# STM32F205RBT6 register map
File version: 1.0
Registers are 32-bit, access not given, reset 0x0 unless marked. A register's access mark holds for its fields unless they carry their own. Offsets are from the block's base; [hi:lo] are bit positions; {n}, {i} and the like mark numbered series.

## ADC1
Base 0x40012000
Same registers: ADC2 0x40012100, ADC3 0x40012300
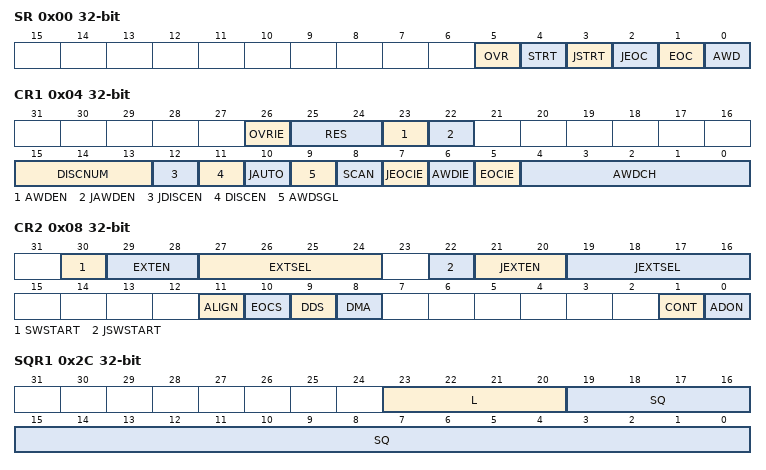
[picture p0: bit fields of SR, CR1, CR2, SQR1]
0x00 SR
  [5] OVR, [4] STRT, [3] JSTRT, [2] JEOC, [1] EOC, [0] AWD
0x04 CR1
  [26] OVRIE, [25:24] RES, [23] AWDEN, [22] JAWDEN, [15:13] DISCNUM, [12] JDISCEN, [11] DISCEN, [10] JAUTO, [9] AWDSGL, [8] SCAN, [7] JEOCIE, [6] AWDIE, [5] EOCIE, [4:0] AWDCH
0x08 CR2
  [30] SWSTART, [29:28] EXTEN, [27:24] EXTSEL, [22] JSWSTART, [21:20] JEXTEN, [19:16] JEXTSEL, [11] ALIGN, [10] EOCS, [9] DDS, [8] DMA, [1] CONT, [0] ADON
0x0C SMPR1
  [31:0] SMP
0x10 SMPR2
  [31:0] SMP
{0x10+4i} JOFR{i} (i=1..4)
  [11:0] JOFFSET{i}
0x24 HTR
  [11:0] HT
0x28 LTR
  [11:0] LT
0x2C SQR1
  [23:20] L, [19:0] SQ
0x30 SQR2
  [29:0] SQ
0x34 SQR3
  [29:0] SQ
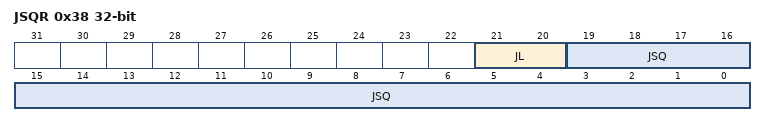
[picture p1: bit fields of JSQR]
0x38 JSQR
  [21:20] JL, [19:0] JSQ
{0x38+4i} JDR{i} (i=1..4)
  [15:0] JDATA
0x4C DR
  [15:0] DATA

## SDIO
Base 0x40012C00
0x00 POWER
  [1:0] PWRCTRL
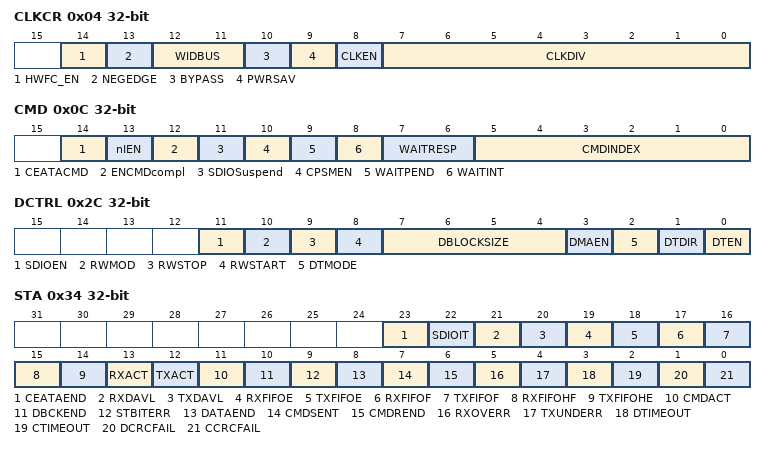
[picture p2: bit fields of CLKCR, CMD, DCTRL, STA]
0x04 CLKCR
  [14] HWFC_EN, [13] NEGEDGE, [12:11] WIDBUS, [10] BYPASS, [9] PWRSAV, [8] CLKEN, [7:0] CLKDIV
0x08 ARG
  [31:0] CMDARG
0x0C CMD
  [14] CEATACMD, [13] nIEN, [12] ENCMDcompl, [11] SDIOSuspend, [10] CPSMEN, [9] WAITPEND, [8] WAITINT, [7:6] WAITRESP, [5:0] CMDINDEX
0x10 RESPCMD
  [5:0] RESPCMD
{0x10+4i} RESP{i} (i=1..4)
  [31:0] CARDSTATUS{i}
0x24 DTIMER
  [31:0] DATATIME
0x28 DLEN
  [24:0] DATALENGTH
0x2C DCTRL
  [11] SDIOEN, [10] RWMOD, [9] RWSTOP, [8] RWSTART, [7:4] DBLOCKSIZE, [3] DMAEN, [2] DTMODE, [1] DTDIR, [0] DTEN
0x30 DCOUNT
  [24:0] DATACOUNT
0x34 STA
  [23] CEATAEND, [22] SDIOIT, [21] RXDAVL, [20] TXDAVL, [19] RXFIFOE, [18] TXFIFOE, [17] RXFIFOF, [16] TXFIFOF, [15] RXFIFOHF, [14] TXFIFOHE, [13] RXACT, [12] TXACT, [11] CMDACT, [10] DBCKEND, [9] STBITERR, [8] DATAEND, [7] CMDSENT, [6] CMDREND, [5] RXOVERR, [4] TXUNDERR, [3] DTIMEOUT, [2] CTIMEOUT, [1] DCRCFAIL, [0] CCRCFAIL
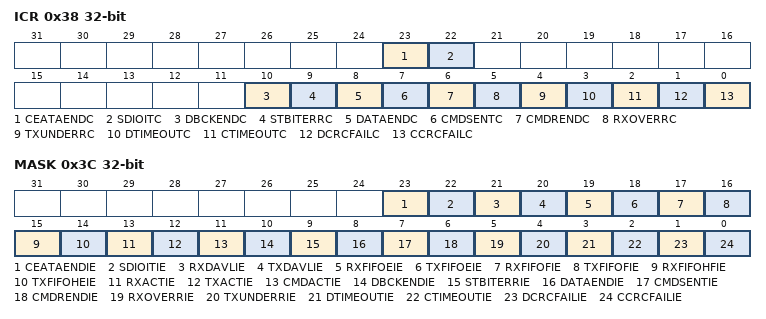
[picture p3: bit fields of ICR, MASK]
0x38 ICR
  [23] CEATAENDC, [22] SDIOITC, [10] DBCKENDC, [9] STBITERRC, [8] DATAENDC, [7] CMDSENTC, [6] CMDRENDC, [5] RXOVERRC, [4] TXUNDERRC, [3] DTIMEOUTC, [2] CTIMEOUTC, [1] DCRCFAILC, [0] CCRCFAILC
0x3C MASK
  [23] CEATAENDIE, [22] SDIOITIE, [21] RXDAVLIE, [20] TXDAVLIE, [19] RXFIFOEIE, [18] TXFIFOEIE, [17] RXFIFOFIE, [16] TXFIFOFIE, [15] RXFIFOHFIE, [14] TXFIFOHEIE, [13] RXACTIE, [12] TXACTIE, [11] CMDACTIE, [10] DBCKENDIE, [9] STBITERRIE, [8] DATAENDIE, [7] CMDSENTIE, [6] CMDRENDIE, [5] RXOVERRIE, [4] TXUNDERRIE, [3] DTIMEOUTIE, [2] CTIMEOUTIE, [1] DCRCFAILIE, [0] CCRCFAILIE
0x48 FIFOCNT
  [23:0] FIFOCOUNT
0x80 FIFO
  [31:0] FIF0Data

## SYSCFG
Base 0x40013800
0x00 MEMRM
  [1:0] MEM_MODE
0x04 PMC
  [23] MII_RMII_SEL
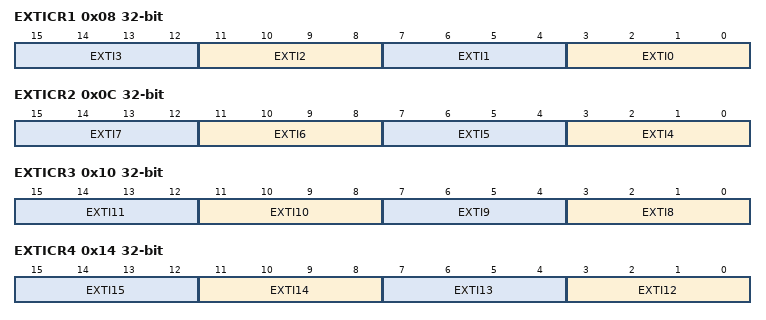
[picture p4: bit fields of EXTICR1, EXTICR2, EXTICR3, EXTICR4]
0x08 EXTICR1
  [4n+3:4n] EXTI{n} (n=0..3)
0x0C EXTICR2
  [4n-13:4n-16] EXTI{n} (n=4..7)
0x10 EXTICR3
  [4n-29:4n-32] EXTI{n} (n=8..11)
0x14 EXTICR4
  [4n-45:4n-48] EXTI{n} (n=12..15)
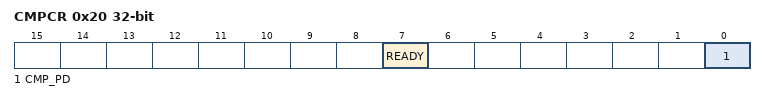
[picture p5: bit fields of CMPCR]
0x20 CMPCR
  [7] READY, [0] CMP_PD

## EXTI
Base 0x40013C00
0x00 IMR
  [22:0] MR
0x04 EMR
  [22:0] MR
0x08 RTSR
  [22:0] TR
0x0C FTSR
  [22:0] TR
0x10 SWIER
  [22:0] SWIER
0x14 PR
  [22:0] PR

## GPIOA
Base 0x40020000
Same registers: GPIOB 0x40020400, GPIOC 0x40020800, GPIOD 0x40020C00, GPIOE 0x40021000, GPIOF 0x40021400, GPIOG 0x40021800, GPIOH 0x40021C00, GPIOI 0x40022000
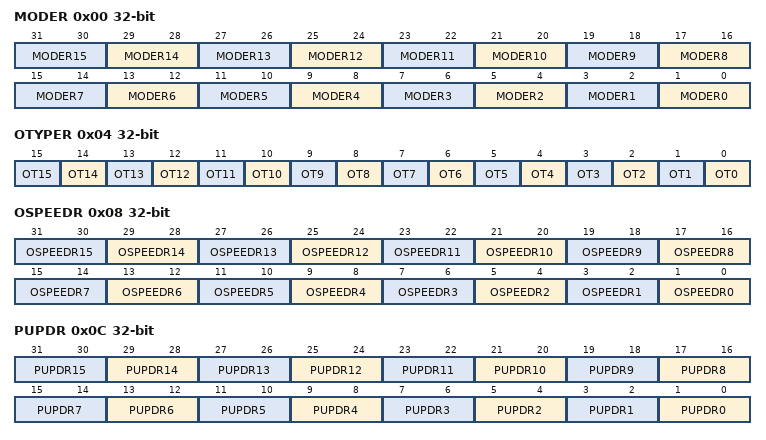
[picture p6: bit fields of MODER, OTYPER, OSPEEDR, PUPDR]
0x00 MODER
  [2n+1:2n] MODER{n} (n=0..15)
0x04 OTYPER
  [n] OT{n} (n=0..15)
0x08 OSPEEDR
  [2n+1:2n] OSPEEDR{n} (n=0..15)
0x0C PUPDR
  [2n+1:2n] PUPDR{n} (n=0..15)
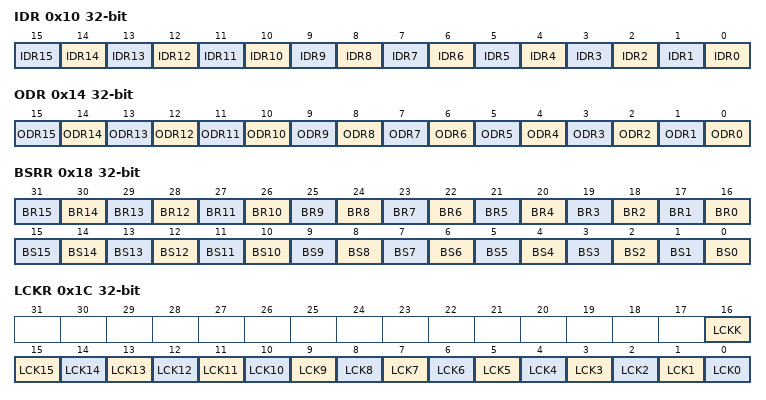
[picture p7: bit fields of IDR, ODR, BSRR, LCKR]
0x10 IDR
  [n] IDR{n} (n=0..15)
0x14 ODR
  [n] ODR{n} (n=0..15)
0x18 BSRR
  [n+16] BR{n} (n=0..15), [n] BS{n} (n=0..15)
0x1C LCKR
  [16] LCKK, [n] LCK{n} (n=0..15)
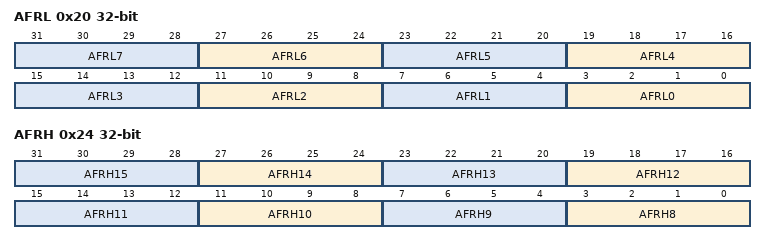
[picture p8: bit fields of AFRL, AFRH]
0x20 AFRL
  [4n+3:4n] AFRL{n} (n=0..7)
0x24 AFRH
  [4n-29:4n-32] AFRH{n} (n=8..15)

## CRC
Base 0x40023000
0x00 DR
  [30:0] DATA
0x04 IDR
  [7:0] DATA
0x08 CR
  [0] RESET

## DMA1
Base 0x40026000
Same registers: DMA2 0x40026400
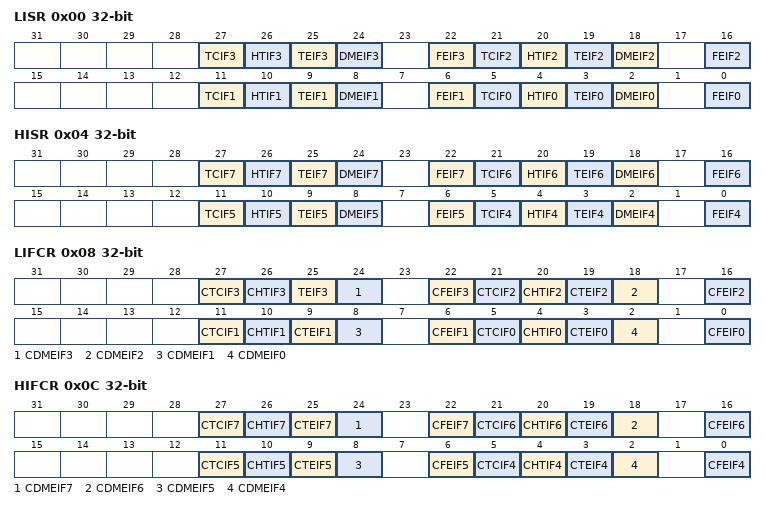
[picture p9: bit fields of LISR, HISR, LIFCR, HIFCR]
0x00 LISR
  [27] TCIF3, [26] HTIF3, [25] TEIF3, [24] DMEIF3, [22] FEIF3, [21] TCIF2, [20] HTIF2, [19] TEIF2, [18] DMEIF2, [16] FEIF2, [11] TCIF1, [10] HTIF1, [9] TEIF1, [8] DMEIF1, [6] FEIF1, [5] TCIF0, [4] HTIF0, [3] TEIF0, [2] DMEIF0, [0] FEIF0
0x04 HISR
  [27] TCIF7, [26] HTIF7, [25] TEIF7, [24] DMEIF7, [22] FEIF7, [21] TCIF6, [20] HTIF6, [19] TEIF6, [18] DMEIF6, [16] FEIF6, [11] TCIF5, [10] HTIF5, [9] TEIF5, [8] DMEIF5, [6] FEIF5, [5] TCIF4, [4] HTIF4, [3] TEIF4, [2] DMEIF4, [0] FEIF4
0x08 LIFCR
  [27] CTCIF3, [26] CHTIF3, [25] TEIF3, [24] CDMEIF3, [22] CFEIF3, [21] CTCIF2, [20] CHTIF2, [19] CTEIF2, [18] CDMEIF2, [16] CFEIF2, [11] CTCIF1, [10] CHTIF1, [9] CTEIF1, [8] CDMEIF1, [6] CFEIF1, [5] CTCIF0, [4] CHTIF0, [3] CTEIF0, [2] CDMEIF0, [0] CFEIF0
0x0C HIFCR
  [27] CTCIF7, [26] CHTIF7, [25] CTEIF7, [24] CDMEIF7, [22] CFEIF7, [21] CTCIF6, [20] CHTIF6, [19] CTEIF6, [18] CDMEIF6, [16] CFEIF6, [11] CTCIF5, [10] CHTIF5, [9] CTEIF5, [8] CDMEIF5, [6] CFEIF5, [5] CTCIF4, [4] CHTIF4, [3] CTEIF4, [2] CDMEIF4, [0] CFEIF4
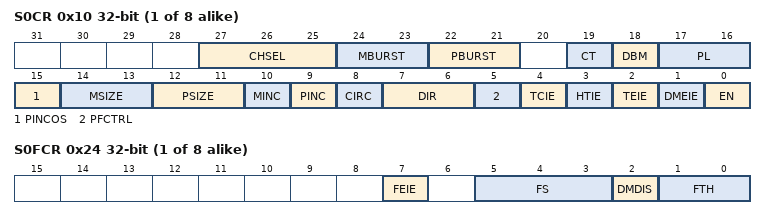
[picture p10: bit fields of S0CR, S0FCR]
{0x10+0x18*i} S{i}CR (i=0..7)
  [27:25] CHSEL, [24:23] MBURST, [22:21] PBURST, [19] CT, [18] DBM, [17:16] PL, [15] PINCOS, [14:13] MSIZE, [12:11] PSIZE, [10] MINC, [9] PINC, [8] CIRC, [7:6] DIR, [5] PFCTRL, [4] TCIE, [3] HTIE, [2] TEIE, [1] DMEIE, [0] EN
{0x14+0x18*i} S{i}NDTR (i=0..7)
  [15:0] NDT
{0x18+0x18*i} S{i}PAR (i=0..7)
  [31:0] PA
{0x1C+0x18*i} S{i}M0AR (i=0..7)
  [31:0] M0A
{0x20+0x18*i} S{i}M1AR (i=0..7)
  [31:0] M1A
{0x24+0x18*i} S{i}FCR (i=0..7)
  [7] FEIE, [5:3] FS, [2] DMDIS, [1:0] FTH
